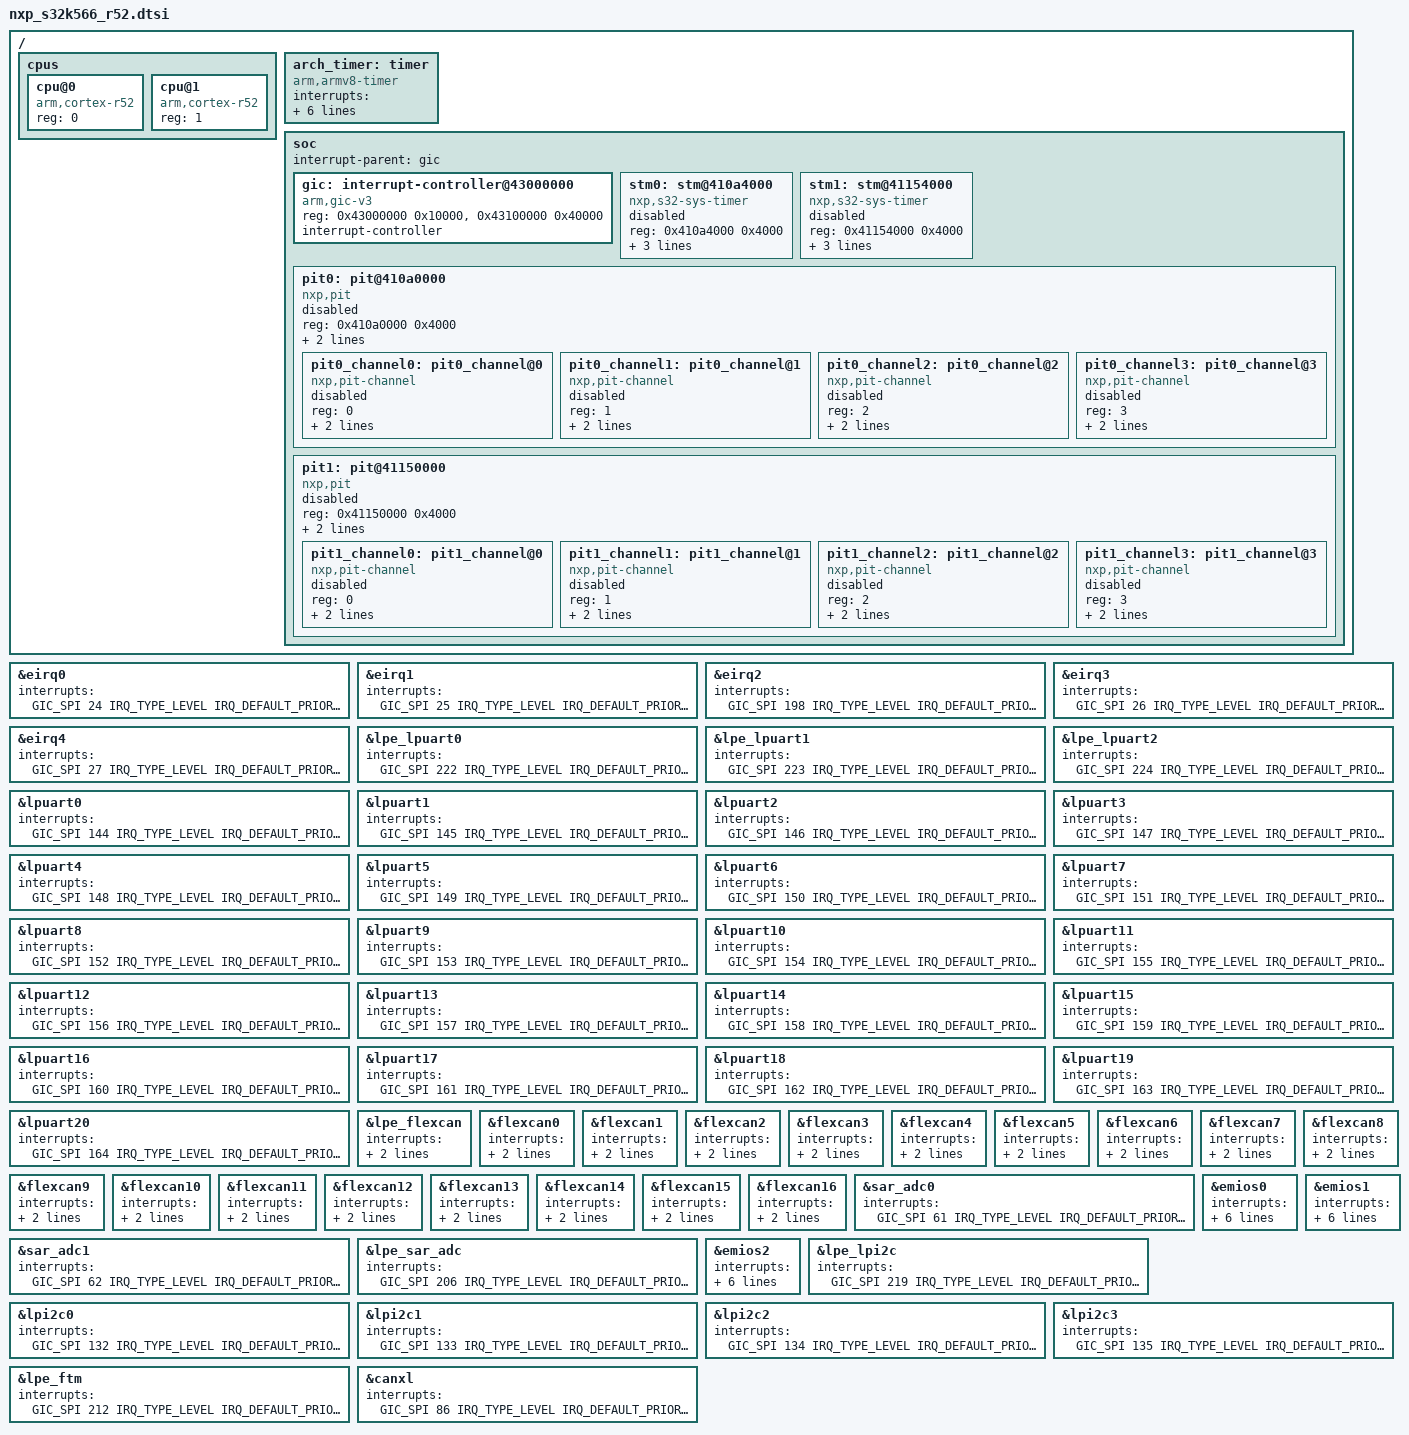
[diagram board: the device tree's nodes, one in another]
/*
 * Copyright 2025 NXP
 *
 * SPDX-License-Identifier: Apache-2.0
 */

#include <arm/armv8-r.dtsi>
#include <zephyr/dt-bindings/interrupt-controller/arm-gic.h>
#include <nxp/nxp_s32k566.dtsi>

/ {
	cpus {
		#address-cells = <1>;
		#size-cells = <0>;

		cpu@0 {
			device_type = "cpu";
			compatible = "arm,cortex-r52";
			reg = <0>;
		};

		cpu@1 {
			device_type = "cpu";
			compatible = "arm,cortex-r52";
			reg = <1>;
		};
	};

	arch_timer: timer {
		compatible = "arm,armv8-timer";
		interrupts = <GIC_PPI 13 IRQ_TYPE_LEVEL IRQ_DEFAULT_PRIORITY>,
			     <GIC_PPI 14 IRQ_TYPE_LEVEL IRQ_DEFAULT_PRIORITY>,
			     <GIC_PPI 11 IRQ_TYPE_LEVEL IRQ_DEFAULT_PRIORITY>,
			     <GIC_PPI 10 IRQ_TYPE_LEVEL IRQ_DEFAULT_PRIORITY>;
		interrupt-parent = <&gic>;
		clock-frequency = <4000000>;
	};

	soc {
		interrupt-parent = <&gic>;

		gic: interrupt-controller@43000000 {
			compatible = "arm,gic-v3", "arm,gic";
			reg = <0x43000000 0x10000>,
			      <0x43100000 0x40000>;
			#address-cells = <0>;
			interrupt-controller;
			#interrupt-cells = <4>;
			status = "okay";
		};

		stm0: stm@410a4000 {
			compatible = "nxp,s32-sys-timer";
			reg = <0x410a4000 0x4000>;
			interrupts = <GIC_SPI 283 IRQ_TYPE_LEVEL IRQ_DEFAULT_PRIORITY>;
			clocks = <&clock NXP_S32_STM0_IPG_CLK>;
			status = "disabled";
		};

		stm1: stm@41154000 {
			compatible = "nxp,s32-sys-timer";
			reg = <0x41154000 0x4000>;
			interrupts = <GIC_SPI 287 IRQ_TYPE_LEVEL IRQ_DEFAULT_PRIORITY>;
			clocks = <&clock NXP_S32_STM1_IPG_CLK>;
			status = "disabled";
		};

		pit0: pit@410a0000 {
			compatible = "nxp,pit";
			reg = <0x410a0000 0x4000>;
			clocks = <&clock NXP_S32_PLTDIV2_CLK>;
			max-load-value = <0xffffffff>;
			status = "disabled";
			#address-cells = <1>;
			#size-cells = <0>;

			pit0_channel0: pit0_channel@0 {
				compatible = "nxp,pit-channel";
				reg = <0>;
				interrupts = <GIC_SPI 271 IRQ_TYPE_LEVEL IRQ_DEFAULT_PRIORITY>;
				status = "disabled";
			};

			pit0_channel1: pit0_channel@1 {
				compatible = "nxp,pit-channel";
				reg = <1>;
				interrupts = <GIC_SPI 272 IRQ_TYPE_LEVEL IRQ_DEFAULT_PRIORITY>;
				status = "disabled";
			};

			pit0_channel2: pit0_channel@2 {
				compatible = "nxp,pit-channel";
				reg = <2>;
				interrupts = <GIC_SPI 273 IRQ_TYPE_LEVEL IRQ_DEFAULT_PRIORITY>;
				status = "disabled";
			};

			pit0_channel3: pit0_channel@3 {
				compatible = "nxp,pit-channel";
				reg = <3>;
				interrupts = <GIC_SPI 274 IRQ_TYPE_LEVEL IRQ_DEFAULT_PRIORITY>;
				status = "disabled";
			};
		};

		pit1: pit@41150000 {
			compatible = "nxp,pit";
			reg = <0x41150000 0x4000>;
			clocks = <&clock NXP_S32_PLTDIV2_CLK>;
			max-load-value = <0xffffffff>;
			status = "disabled";
			#address-cells = <1>;
			#size-cells = <0>;

			pit1_channel0: pit1_channel@0 {
				compatible = "nxp,pit-channel";
				reg = <0>;
				interrupts = <GIC_SPI 275 IRQ_TYPE_LEVEL IRQ_DEFAULT_PRIORITY>;
				status = "disabled";
			};

			pit1_channel1: pit1_channel@1 {
				compatible = "nxp,pit-channel";
				reg = <1>;
				interrupts = <GIC_SPI 276 IRQ_TYPE_LEVEL IRQ_DEFAULT_PRIORITY>;
				status = "disabled";
			};

			pit1_channel2: pit1_channel@2 {
				compatible = "nxp,pit-channel";
				reg = <2>;
				interrupts = <GIC_SPI 277 IRQ_TYPE_LEVEL IRQ_DEFAULT_PRIORITY>;
				status = "disabled";
			};

			pit1_channel3: pit1_channel@3 {
				compatible = "nxp,pit-channel";
				reg = <3>;
				interrupts = <GIC_SPI 278 IRQ_TYPE_LEVEL IRQ_DEFAULT_PRIORITY>;
				status = "disabled";
			};
		};
	};
};

&eirq0 {
	interrupts = <GIC_SPI 24 IRQ_TYPE_LEVEL IRQ_DEFAULT_PRIORITY>;
};

&eirq1 {
	interrupts = <GIC_SPI 25 IRQ_TYPE_LEVEL IRQ_DEFAULT_PRIORITY>;
};

&eirq2 {
	interrupts = <GIC_SPI 198 IRQ_TYPE_LEVEL IRQ_DEFAULT_PRIORITY>;
};

&eirq3 {
	interrupts = <GIC_SPI 26 IRQ_TYPE_LEVEL IRQ_DEFAULT_PRIORITY>;
};

&eirq4 {
	interrupts = <GIC_SPI 27 IRQ_TYPE_LEVEL IRQ_DEFAULT_PRIORITY>;
};

&lpe_lpuart0 {
	interrupts = <GIC_SPI 222 IRQ_TYPE_LEVEL IRQ_DEFAULT_PRIORITY>;
};

&lpe_lpuart1 {
	interrupts = <GIC_SPI 223 IRQ_TYPE_LEVEL IRQ_DEFAULT_PRIORITY>;
};

&lpe_lpuart2 {
	interrupts = <GIC_SPI 224 IRQ_TYPE_LEVEL IRQ_DEFAULT_PRIORITY>;
};

&lpuart0 {
	interrupts = <GIC_SPI 144 IRQ_TYPE_LEVEL IRQ_DEFAULT_PRIORITY>;
};

&lpuart1 {
	interrupts = <GIC_SPI 145 IRQ_TYPE_LEVEL IRQ_DEFAULT_PRIORITY>;
};

&lpuart2 {
	interrupts = <GIC_SPI 146 IRQ_TYPE_LEVEL IRQ_DEFAULT_PRIORITY>;
};

&lpuart3 {
	interrupts = <GIC_SPI 147 IRQ_TYPE_LEVEL IRQ_DEFAULT_PRIORITY>;
};

&lpuart4 {
	interrupts = <GIC_SPI 148 IRQ_TYPE_LEVEL IRQ_DEFAULT_PRIORITY>;
};

&lpuart5 {
	interrupts = <GIC_SPI 149 IRQ_TYPE_LEVEL IRQ_DEFAULT_PRIORITY>;
};

&lpuart6 {
	interrupts = <GIC_SPI 150 IRQ_TYPE_LEVEL IRQ_DEFAULT_PRIORITY>;
};

&lpuart7 {
	interrupts = <GIC_SPI 151 IRQ_TYPE_LEVEL IRQ_DEFAULT_PRIORITY>;
};

&lpuart8 {
	interrupts = <GIC_SPI 152 IRQ_TYPE_LEVEL IRQ_DEFAULT_PRIORITY>;
};

&lpuart9 {
	interrupts = <GIC_SPI 153 IRQ_TYPE_LEVEL IRQ_DEFAULT_PRIORITY>;
};

&lpuart10 {
	interrupts = <GIC_SPI 154 IRQ_TYPE_LEVEL IRQ_DEFAULT_PRIORITY>;
};

&lpuart11 {
	interrupts = <GIC_SPI 155 IRQ_TYPE_LEVEL IRQ_DEFAULT_PRIORITY>;
};

&lpuart12 {
	interrupts = <GIC_SPI 156 IRQ_TYPE_LEVEL IRQ_DEFAULT_PRIORITY>;
};

&lpuart13 {
	interrupts = <GIC_SPI 157 IRQ_TYPE_LEVEL IRQ_DEFAULT_PRIORITY>;
};

&lpuart14 {
	interrupts = <GIC_SPI 158 IRQ_TYPE_LEVEL IRQ_DEFAULT_PRIORITY>;
};

&lpuart15 {
	interrupts = <GIC_SPI 159 IRQ_TYPE_LEVEL IRQ_DEFAULT_PRIORITY>;
};

&lpuart16 {
	interrupts = <GIC_SPI 160 IRQ_TYPE_LEVEL IRQ_DEFAULT_PRIORITY>;
};

&lpuart17 {
	interrupts = <GIC_SPI 161 IRQ_TYPE_LEVEL IRQ_DEFAULT_PRIORITY>;
};

&lpuart18 {
	interrupts = <GIC_SPI 162 IRQ_TYPE_LEVEL IRQ_DEFAULT_PRIORITY>;
};

&lpuart19 {
	interrupts = <GIC_SPI 163 IRQ_TYPE_LEVEL IRQ_DEFAULT_PRIORITY>;
};

&lpuart20 {
	interrupts = <GIC_SPI 164 IRQ_TYPE_LEVEL IRQ_DEFAULT_PRIORITY>;
};

&lpe_flexcan {
	interrupts = <GIC_SPI 217 IRQ_TYPE_LEVEL IRQ_DEFAULT_PRIORITY>,
		     <GIC_SPI 218 IRQ_TYPE_LEVEL IRQ_DEFAULT_PRIORITY>;
};

&flexcan0 {
	interrupts = <GIC_SPI 95 IRQ_TYPE_LEVEL IRQ_DEFAULT_PRIORITY>,
		     <GIC_SPI 96 IRQ_TYPE_LEVEL IRQ_DEFAULT_PRIORITY>;
};

&flexcan1 {
	interrupts = <GIC_SPI 97 IRQ_TYPE_LEVEL IRQ_DEFAULT_PRIORITY>,
		     <GIC_SPI 98 IRQ_TYPE_LEVEL IRQ_DEFAULT_PRIORITY>;
};

&flexcan2 {
	interrupts = <GIC_SPI 99 IRQ_TYPE_LEVEL IRQ_DEFAULT_PRIORITY>,
		     <GIC_SPI 100 IRQ_TYPE_LEVEL IRQ_DEFAULT_PRIORITY>;
};

&flexcan3 {
	interrupts = <GIC_SPI 101 IRQ_TYPE_LEVEL IRQ_DEFAULT_PRIORITY>,
		     <GIC_SPI 102 IRQ_TYPE_LEVEL IRQ_DEFAULT_PRIORITY>;
};

&flexcan4 {
	interrupts = <GIC_SPI 103 IRQ_TYPE_LEVEL IRQ_DEFAULT_PRIORITY>,
		     <GIC_SPI 104 IRQ_TYPE_LEVEL IRQ_DEFAULT_PRIORITY>;
};

&flexcan5 {
	interrupts = <GIC_SPI 105 IRQ_TYPE_LEVEL IRQ_DEFAULT_PRIORITY>,
		     <GIC_SPI 106 IRQ_TYPE_LEVEL IRQ_DEFAULT_PRIORITY>;
};

&flexcan6 {
	interrupts = <GIC_SPI 107 IRQ_TYPE_LEVEL IRQ_DEFAULT_PRIORITY>,
		     <GIC_SPI 108 IRQ_TYPE_LEVEL IRQ_DEFAULT_PRIORITY>;
};

&flexcan7 {
	interrupts = <GIC_SPI 109 IRQ_TYPE_LEVEL IRQ_DEFAULT_PRIORITY>,
		     <GIC_SPI 110 IRQ_TYPE_LEVEL IRQ_DEFAULT_PRIORITY>;
};

&flexcan8 {
	interrupts = <GIC_SPI 111 IRQ_TYPE_LEVEL IRQ_DEFAULT_PRIORITY>,
		     <GIC_SPI 112 IRQ_TYPE_LEVEL IRQ_DEFAULT_PRIORITY>;
};

&flexcan9 {
	interrupts = <GIC_SPI 113 IRQ_TYPE_LEVEL IRQ_DEFAULT_PRIORITY>,
		     <GIC_SPI 114 IRQ_TYPE_LEVEL IRQ_DEFAULT_PRIORITY>;
};

&flexcan10 {
	interrupts = <GIC_SPI 115 IRQ_TYPE_LEVEL IRQ_DEFAULT_PRIORITY>,
		     <GIC_SPI 116 IRQ_TYPE_LEVEL IRQ_DEFAULT_PRIORITY>;
};

&flexcan11 {
	interrupts = <GIC_SPI 117 IRQ_TYPE_LEVEL IRQ_DEFAULT_PRIORITY>,
		     <GIC_SPI 118 IRQ_TYPE_LEVEL IRQ_DEFAULT_PRIORITY>;
};

&flexcan12 {
	interrupts = <GIC_SPI 119 IRQ_TYPE_LEVEL IRQ_DEFAULT_PRIORITY>,
		     <GIC_SPI 120 IRQ_TYPE_LEVEL IRQ_DEFAULT_PRIORITY>;
};

&flexcan13 {
	interrupts = <GIC_SPI 121 IRQ_TYPE_LEVEL IRQ_DEFAULT_PRIORITY>,
		     <GIC_SPI 122 IRQ_TYPE_LEVEL IRQ_DEFAULT_PRIORITY>;
};

&flexcan14 {
	interrupts = <GIC_SPI 123 IRQ_TYPE_LEVEL IRQ_DEFAULT_PRIORITY>,
		     <GIC_SPI 124 IRQ_TYPE_LEVEL IRQ_DEFAULT_PRIORITY>;
};

&flexcan15 {
	interrupts = <GIC_SPI 125 IRQ_TYPE_LEVEL IRQ_DEFAULT_PRIORITY>,
		     <GIC_SPI 126 IRQ_TYPE_LEVEL IRQ_DEFAULT_PRIORITY>;
};

&flexcan16 {
	interrupts = <GIC_SPI 127 IRQ_TYPE_LEVEL IRQ_DEFAULT_PRIORITY>,
		     <GIC_SPI 128 IRQ_TYPE_LEVEL IRQ_DEFAULT_PRIORITY>;
};

&sar_adc0 {
	interrupts = <GIC_SPI 61 IRQ_TYPE_LEVEL IRQ_DEFAULT_PRIORITY>;
};

&sar_adc1 {
	interrupts = <GIC_SPI 62 IRQ_TYPE_LEVEL IRQ_DEFAULT_PRIORITY>;
};

&lpe_sar_adc {
	interrupts = <GIC_SPI 206 IRQ_TYPE_LEVEL IRQ_DEFAULT_PRIORITY>;
};

&emios0 {
	interrupts = <GIC_SPI 64 IRQ_TYPE_LEVEL IRQ_DEFAULT_PRIORITY>,
		     <GIC_SPI 65 IRQ_TYPE_LEVEL IRQ_DEFAULT_PRIORITY>,
		     <GIC_SPI 66 IRQ_TYPE_LEVEL IRQ_DEFAULT_PRIORITY>,
		     <GIC_SPI 67 IRQ_TYPE_LEVEL IRQ_DEFAULT_PRIORITY>,
		     <GIC_SPI 68 IRQ_TYPE_LEVEL IRQ_DEFAULT_PRIORITY>,
		     <GIC_SPI 69 IRQ_TYPE_LEVEL IRQ_DEFAULT_PRIORITY>;
};

&emios1 {
	interrupts = <GIC_SPI 70 IRQ_TYPE_LEVEL IRQ_DEFAULT_PRIORITY>,
		     <GIC_SPI 71 IRQ_TYPE_LEVEL IRQ_DEFAULT_PRIORITY>,
		     <GIC_SPI 72 IRQ_TYPE_LEVEL IRQ_DEFAULT_PRIORITY>,
		     <GIC_SPI 73 IRQ_TYPE_LEVEL IRQ_DEFAULT_PRIORITY>,
		     <GIC_SPI 74 IRQ_TYPE_LEVEL IRQ_DEFAULT_PRIORITY>,
		     <GIC_SPI 75 IRQ_TYPE_LEVEL IRQ_DEFAULT_PRIORITY>;
};

&emios2 {
	interrupts = <GIC_SPI 76 IRQ_TYPE_LEVEL IRQ_DEFAULT_PRIORITY>,
		     <GIC_SPI 78 IRQ_TYPE_LEVEL IRQ_DEFAULT_PRIORITY>,
		     <GIC_SPI 79 IRQ_TYPE_LEVEL IRQ_DEFAULT_PRIORITY>,
		     <GIC_SPI 80 IRQ_TYPE_LEVEL IRQ_DEFAULT_PRIORITY>,
		     <GIC_SPI 81 IRQ_TYPE_LEVEL IRQ_DEFAULT_PRIORITY>,
		     <GIC_SPI 82 IRQ_TYPE_LEVEL IRQ_DEFAULT_PRIORITY>;
};

&lpe_lpi2c {
	interrupts = <GIC_SPI 219 IRQ_TYPE_LEVEL IRQ_DEFAULT_PRIORITY>;
};

&lpi2c0 {
	interrupts = <GIC_SPI 132 IRQ_TYPE_LEVEL IRQ_DEFAULT_PRIORITY>;
};

&lpi2c1 {
	interrupts = <GIC_SPI 133 IRQ_TYPE_LEVEL IRQ_DEFAULT_PRIORITY>;
};

&lpi2c2 {
	interrupts = <GIC_SPI 134 IRQ_TYPE_LEVEL IRQ_DEFAULT_PRIORITY>;
};

&lpi2c3 {
	interrupts = <GIC_SPI 135 IRQ_TYPE_LEVEL IRQ_DEFAULT_PRIORITY>;
};

&lpe_ftm {
	interrupts = <GIC_SPI 212 IRQ_TYPE_LEVEL IRQ_DEFAULT_PRIORITY>;
};

&canxl {
	interrupts = <GIC_SPI 86 IRQ_TYPE_LEVEL IRQ_DEFAULT_PRIORITY>;
	interrupt-names = "rx_tx_mru_error";
};
